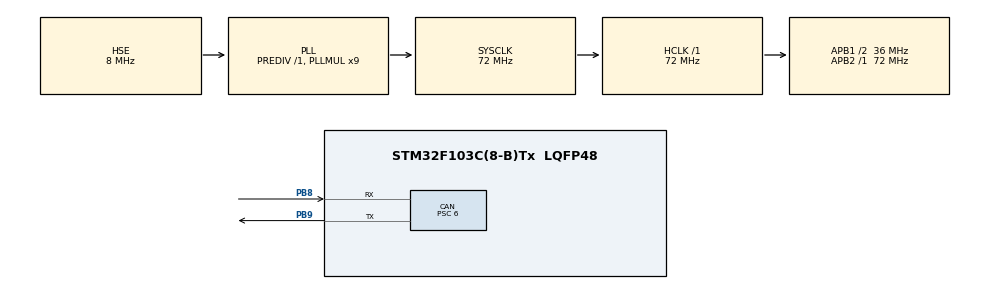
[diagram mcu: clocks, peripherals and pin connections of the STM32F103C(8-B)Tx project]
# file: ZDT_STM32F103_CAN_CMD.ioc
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CAN.ABOM=ENABLE
CAN.BS1=CAN_BS1_9TQ
CAN.BS2=CAN_BS2_2TQ
CAN.CalculateBaudRate=499999
CAN.CalculateTimeBit=2000
CAN.CalculateTimeQuantum=166.66666666666669
CAN.Prescaler=6
Mcu.Family=STM32F1
Mcu.Name=STM32F103C(8-B)Tx
Mcu.Package=LQFP48
NVIC.PriorityGroup=NVIC_PRIORITYGROUP_4
NVIC.USB_LP_CAN1_RX0_IRQn=true\:0\:0\:false\:false\:true\:true\:true\:true
PA13.Mode=Serial_Wire
PA13.Signal=SYS_JTMS-SWDIO
PA14.Mode=Serial_Wire
PA14.Signal=SYS_JTCK-SWCLK
PB8.Mode=CAN_Activate
PB8.Signal=CAN_RX
PB9.Mode=CAN_Activate
PB9.Signal=CAN_TX
PD0-OSC_IN.Mode=HSE-External-Oscillator
PD0-OSC_IN.Signal=RCC_OSC_IN
PD1-OSC_OUT.Mode=HSE-External-Oscillator
PD1-OSC_OUT.Signal=RCC_OSC_OUT
ProjectManager.HeapSize=0x200
ProjectManager.StackSize=0xC00
ProjectManager.TargetToolchain=MDK-ARM V5
RCC.AHBFreq_Value=72000000
RCC.APB1CLKDivider=RCC_HCLK_DIV2
RCC.APB1Freq_Value=36000000
RCC.APB1TimFreq_Value=72000000
RCC.APB2Freq_Value=72000000
RCC.APB2TimFreq_Value=72000000
RCC.HCLKFreq_Value=72000000
RCC.PLLMUL=RCC_PLL_MUL9
RCC.PLLSourceVirtual=RCC_PLLSOURCE_HSE
RCC.SYSCLKFreq_VALUE=72000000
RCC.SYSCLKSource=RCC_SYSCLKSOURCE_PLLCLK
RCC.USBFreq_Value=72000000
board=custom

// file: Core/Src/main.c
/* USER CODE BEGIN Header */
/**
  ******************************************************************************
  * @file           : main.c
  * @brief          : Main program body
  ******************************************************************************
  * @attention
  *
  * Copyright (c) 2026 STMicroelectronics.
  * All rights reserved.
  *
  * This software is licensed under terms that can be found in the LICENSE file
  * in the root directory of this software component.
  * If no LICENSE file comes with this software, it is provided AS-IS.
  *
  ******************************************************************************
  */
/* USER CODE END Header */
#include "main.h"
#include "can.h"
#include "gpio.h"

/* USER CODE BEGIN Includes */

#include "X_V2.h"

/* USER CODE END Includes */

void SystemClock_Config(void);

int main(void)
{

  /* MCU Configuration--------------------------------------------------------*/

  /* Reset of all peripherals, Initializes the Flash interface and the Systick. */
  HAL_Init();

  /* Configure the system clock */
  SystemClock_Config();

  /* Initialize all configured peripherals */
  MX_GPIO_Init();
  MX_CAN_Init();
  /* USER CODE BEGIN 2 */
	USER_CAN1_Filter_Init();																	// 初始化CAN滤波器
	if(HAL_CAN_Start(&hcan) != HAL_OK) { Error_Handler(); }	// 启动CAN控制器
	if(HAL_CAN_ActivateNotification(&hcan, CAN_IT_RX_FIFO0_MSG_PENDING) != HAL_OK) { Error_Handler(); }	// 使能CAN控制器接收中断

/**********************************************************
***	上电延时500毫秒等待闭环初始化完毕
**********************************************************/
	HAL_Delay(500);

/**********************************************************
***	加载命令到多电机命令缓存上：
			电机1，直通限速位置模式限电流控制：方向CCW，转速2000.0RPM，相对位置运动-3600.0°，限制最大电流2000mA
			电机2，直通限速位置模式限电流控制：方向CCW，转速1000.0RPM，相对位置运动-1800.0°，限制最大电流3000mA
			电机3，直通限速位置模式限电流控制：方向CCW，转速1500.0RPM，相对位置运动-2700.0°，限制最大电流1500mA
			电机4，直通限速位置模式限电流控制：方向CCW，转速2000.0RPM，相对位置运动-3200.0°，限制最大电流2000mA
**********************************************************/
  X_V2_MMCL_Bypass_Pos_LV_LC_Control(1, 1, 2000.0f, 3600.0f, 0, 0, 2000);
	X_V2_MMCL_Bypass_Pos_LV_LC_Control(2, 1, 1000.0f, 1800.0f, 0, 0, 3000);
	X_V2_MMCL_Bypass_Pos_LV_LC_Control(3, 1, 1500.0f, 2700.0f, 0, 0, 1500);
	X_V2_MMCL_Bypass_Pos_LV_LC_Control(4, 1, 2000.0f, 3200.0f, 0, 0, 2000);

/**********************************************************
***	广播地址0发送多电机命令给所有电机
**********************************************************/
	X_V2_Multi_Motor_Cmd(0);

/**********************************************************
	*	等待返回命令
***	返回数据缓存在can.rxData数组上，长度为can.CAN_RxMsg.DLC,
***	电机地址为帧ID右移8位：can.CAN_RxMsg.ExtId >> 8
	*	can.rxFrameFlag在stm32f1xx_it.h中USB_LP_CAN1_RX0_IRQHandler中断函数里接收数据和置位
**********************************************************/
	while(can.rxFrameFlag == false); can.rxFrameFlag = false;

  /* USER CODE END 2 */

  /* Infinite loop */
  while (1)
  {

  }
}

void SystemClock_Config(void)
{
  RCC_OscInitTypeDef RCC_OscInitStruct = {0};
  RCC_ClkInitTypeDef RCC_ClkInitStruct = {0};

  /** Initializes the RCC Oscillators according to the specified parameters
  * in the RCC_OscInitTypeDef structure.
  */
  RCC_OscInitStruct.OscillatorType = RCC_OSCILLATORTYPE_HSE;
  RCC_OscInitStruct.HSEState = RCC_HSE_ON;
  RCC_OscInitStruct.HSEPredivValue = RCC_HSE_PREDIV_DIV1;
  RCC_OscInitStruct.HSIState = RCC_HSI_ON;
  RCC_OscInitStruct.PLL.PLLState = RCC_PLL_ON;
  RCC_OscInitStruct.PLL.PLLSource = RCC_PLLSOURCE_HSE;
  RCC_OscInitStruct.PLL.PLLMUL = RCC_PLL_MUL9;
  if (HAL_RCC_OscConfig(&RCC_OscInitStruct) != HAL_OK)
  {
    Error_Handler();
  }

  /** Initializes the CPU, AHB and APB buses clocks
  */
  RCC_ClkInitStruct.ClockType = RCC_CLOCKTYPE_HCLK|RCC_CLOCKTYPE_SYSCLK
                              |RCC_CLOCKTYPE_PCLK1|RCC_CLOCKTYPE_PCLK2;
  RCC_ClkInitStruct.SYSCLKSource = RCC_SYSCLKSOURCE_PLLCLK;
  RCC_ClkInitStruct.AHBCLKDivider = RCC_SYSCLK_DIV1;
  RCC_ClkInitStruct.APB1CLKDivider = RCC_HCLK_DIV2;
  RCC_ClkInitStruct.APB2CLKDivider = RCC_HCLK_DIV1;

  if (HAL_RCC_ClockConfig(&RCC_ClkInitStruct, FLASH_LATENCY_2) != HAL_OK)
  {
    Error_Handler();
  }
}

void Error_Handler(void)
{
  __disable_irq();
  while (1)
  {
  }
}
